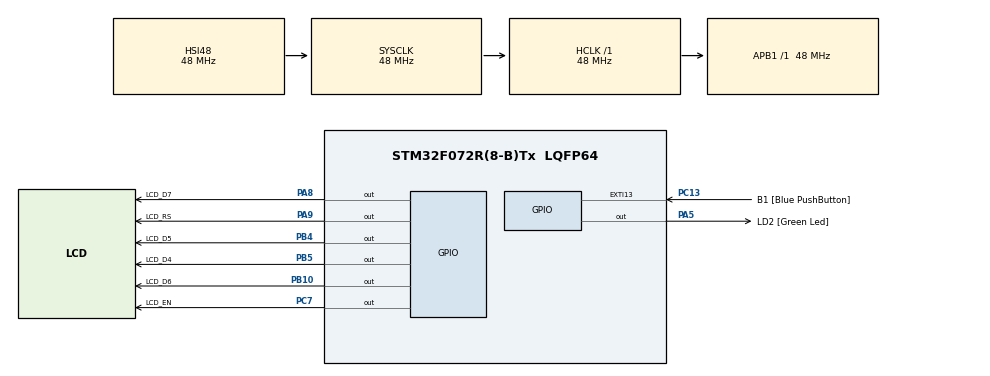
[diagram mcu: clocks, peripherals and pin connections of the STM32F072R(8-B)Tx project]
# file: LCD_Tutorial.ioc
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Mcu.Family=STM32F0
Mcu.Name=STM32F072R(8-B)Tx
Mcu.Package=LQFP64
PA13.GPIO_Label=TMS
PA13.Mode=Serial_Wire
PA13.Signal=SYS_SWDIO
PA14.GPIO_Label=TCK
PA14.Mode=Serial_Wire
PA14.Signal=SYS_SWCLK
PA2.GPIO_Label=USART_TX
PA2.GPIO_Mode=GPIO_MODE_AF_PP
PA2.GPIO_PuPd=GPIO_NOPULL
PA2.GPIO_Speed=GPIO_SPEED_FREQ_LOW
PA2.Signal=USART2_TX
PA3.GPIO_Label=USART_RX
PA3.GPIO_Mode=GPIO_MODE_AF_PP
PA3.GPIO_PuPd=GPIO_NOPULL
PA3.GPIO_Speed=GPIO_SPEED_FREQ_LOW
PA3.Signal=USART2_RX
PA5.GPIO_Label=LD2 [Green Led]
PA5.GPIO_Mode=GPIO_MODE_OUTPUT_PP
PA5.GPIO_PuPd=GPIO_NOPULL
PA5.GPIO_Speed=GPIO_SPEED_FREQ_LOW
PA5.Signal=GPIO_Output
PA8.GPIO_Label=LCD_D7
PA8.Signal=GPIO_Output
PA9.GPIO_Label=LCD_RS
PA9.Signal=GPIO_Output
PB10.GPIO_Label=LCD_D6
PB10.Signal=GPIO_Output
PB4.GPIO_Label=LCD_D5
PB4.Signal=GPIO_Output
PB5.GPIO_Label=LCD_D4
PB5.GPIO_Speed=GPIO_SPEED_FREQ_LOW
PB5.Signal=GPIO_Output
PC13.GPIO_Label=B1 [Blue PushButton]
PC13.GPIO_ModeDefaultEXTI=GPIO_MODE_IT_FALLING
PC13.Signal=GPXTI13
PC14-OSC32_IN.Signal=RCC_OSC32_IN
PC15-OSC32_OUT.Signal=RCC_OSC32_OUT
PC7.GPIO_Label=LCD_EN
PC7.Signal=GPIO_Output
PF0-OSC_IN.Signal=RCC_OSC_IN
PF1-OSC_OUT.Signal=RCC_OSC_OUT
ProjectManager.HeapSize=0x200
ProjectManager.StackSize=0x400
ProjectManager.TargetToolchain=MDK-ARM V5
RCC.AHBFreq_Value=48000000
RCC.APB1Freq_Value=48000000
RCC.APB1TimFreq_Value=48000000
RCC.FLatency-AdvancedSettings=FLASH_LATENCY_1
RCC.HCLKFreq_Value=48000000
RCC.PLLDivider=RCC_PREDIV_DIV2
RCC.PLLMUL=RCC_PLL_MUL12
RCC.PREFETCH_ENABLE-AdvancedSettings=1
RCC.SYSCLKFreq_VALUE=48000000
RCC.SYSCLKSource=RCC_SYSCLKSOURCE_HSI48
board=NUCLEO-F072RB

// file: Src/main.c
/* USER CODE BEGIN Header */
/**
  ******************************************************************************
  * @file           : main.c
  * @brief          : Main program body
  ******************************************************************************
  * @attention
  *
  * <h2><center>&copy; Copyright (c) 2020 STMicroelectronics.
  * All rights reserved.</center></h2>
  *
  * This software component is licensed by ST under BSD 3-Clause license,
  * the "License"; You may not use this file except in compliance with the
  * License. You may obtain a copy of the License at:
  *                        opensource.org/licenses/BSD-3-Clause
  *
  ******************************************************************************
  */
/* USER CODE END Header */

#include "main.h"

/* USER CODE BEGIN Includes */
#include "stdio.h"
#include "LCD.h"

/* USER CODE END Includes */

/* USER CODE BEGIN PM */

char line1[16];
int counter=0;

/* USER CODE END PM */

void SystemClock_Config(void);
static void MX_GPIO_Init(void);

int main(void)
{

  /* MCU Configuration--------------------------------------------------------*/

  /* Reset of all peripherals, Initializes the Flash interface and the Systick. */
  HAL_Init();

  /* Configure the system clock */
  SystemClock_Config();

  /* Initialize all configured peripherals */
  MX_GPIO_Init();
  /* USER CODE BEGIN 2 */
  lcd_init(_LCD_4BIT, _LCD_FONT_5x8, _LCD_2LINE);
	lcd_print(1,1,"Hello World");
  HAL_Delay(1000);
  lcd_clear();

  /* USER CODE END 2 */

  /* Infinite loop */
  while (1)
  {

    /* USER CODE BEGIN 3 */
	counter++;
	sprintf(line1,"Counter = %d ",counter);
	lcd_print(1,1,line1);
	HAL_Delay(1000);
  }
  /* USER CODE END 3 */
}

void SystemClock_Config(void)
{
  RCC_OscInitTypeDef RCC_OscInitStruct = {0};
  RCC_ClkInitTypeDef RCC_ClkInitStruct = {0};

  /** Initializes the CPU, AHB and APB busses clocks
  */
  RCC_OscInitStruct.OscillatorType = RCC_OSCILLATORTYPE_HSI48;
  RCC_OscInitStruct.HSI48State = RCC_HSI48_ON;
  RCC_OscInitStruct.PLL.PLLState = RCC_PLL_NONE;
  if (HAL_RCC_OscConfig(&RCC_OscInitStruct) != HAL_OK)
  {
    Error_Handler();
  }
  /** Initializes the CPU, AHB and APB busses clocks
  */
  RCC_ClkInitStruct.ClockType = RCC_CLOCKTYPE_HCLK|RCC_CLOCKTYPE_SYSCLK
                              |RCC_CLOCKTYPE_PCLK1;
  RCC_ClkInitStruct.SYSCLKSource = RCC_SYSCLKSOURCE_HSI48;
  RCC_ClkInitStruct.AHBCLKDivider = RCC_SYSCLK_DIV1;
  RCC_ClkInitStruct.APB1CLKDivider = RCC_HCLK_DIV1;

  if (HAL_RCC_ClockConfig(&RCC_ClkInitStruct, FLASH_LATENCY_1) != HAL_OK)
  {
    Error_Handler();
  }
}

static void MX_GPIO_Init(void)
{
  GPIO_InitTypeDef GPIO_InitStruct = {0};

  /* GPIO Ports Clock Enable */
  __HAL_RCC_GPIOC_CLK_ENABLE();
  __HAL_RCC_GPIOF_CLK_ENABLE();
  __HAL_RCC_GPIOA_CLK_ENABLE();
  __HAL_RCC_GPIOB_CLK_ENABLE();

  /*Configure GPIO pin Output Level */
  HAL_GPIO_WritePin(GPIOA, LD2_Pin|LCD_D7_Pin|LCD_RS_Pin, GPIO_PIN_RESET);

  /*Configure GPIO pin Output Level */
  HAL_GPIO_WritePin(GPIOB, LCD_D6_Pin|LCD_D5_Pin|LCD_D4_Pin, GPIO_PIN_RESET);

  /*Configure GPIO pin Output Level */
  HAL_GPIO_WritePin(LCD_EN_GPIO_Port, LCD_EN_Pin, GPIO_PIN_RESET);

  /*Configure GPIO pin : B1_Pin */
  GPIO_InitStruct.Pin = B1_Pin;
  GPIO_InitStruct.Mode = GPIO_MODE_IT_FALLING;
  GPIO_InitStruct.Pull = GPIO_NOPULL;
  HAL_GPIO_Init(B1_GPIO_Port, &GPIO_InitStruct);

  /*Configure GPIO pins : USART_TX_Pin USART_RX_Pin */
  GPIO_InitStruct.Pin = USART_TX_Pin|USART_RX_Pin;
  GPIO_InitStruct.Mode = GPIO_MODE_AF_PP;
  GPIO_InitStruct.Pull = GPIO_NOPULL;
  GPIO_InitStruct.Speed = GPIO_SPEED_FREQ_LOW;
  GPIO_InitStruct.Alternate = GPIO_AF1_USART2;
  HAL_GPIO_Init(GPIOA, &GPIO_InitStruct);

  /*Configure GPIO pins : LD2_Pin LCD_D7_Pin LCD_RS_Pin */
  GPIO_InitStruct.Pin = LD2_Pin|LCD_D7_Pin|LCD_RS_Pin;
  GPIO_InitStruct.Mode = GPIO_MODE_OUTPUT_PP;
  GPIO_InitStruct.Pull = GPIO_NOPULL;
  GPIO_InitStruct.Speed = GPIO_SPEED_FREQ_LOW;
  HAL_GPIO_Init(GPIOA, &GPIO_InitStruct);

  /*Configure GPIO pins : LCD_D6_Pin LCD_D5_Pin LCD_D4_Pin */
  GPIO_InitStruct.Pin = LCD_D6_Pin|LCD_D5_Pin|LCD_D4_Pin;
  GPIO_InitStruct.Mode = GPIO_MODE_OUTPUT_PP;
  GPIO_InitStruct.Pull = GPIO_NOPULL;
  GPIO_InitStruct.Speed = GPIO_SPEED_FREQ_LOW;
  HAL_GPIO_Init(GPIOB, &GPIO_InitStruct);

  /*Configure GPIO pin : LCD_EN_Pin */
  GPIO_InitStruct.Pin = LCD_EN_Pin;
  GPIO_InitStruct.Mode = GPIO_MODE_OUTPUT_PP;
  GPIO_InitStruct.Pull = GPIO_NOPULL;
  GPIO_InitStruct.Speed = GPIO_SPEED_FREQ_LOW;
  HAL_GPIO_Init(LCD_EN_GPIO_Port, &GPIO_InitStruct);

}

void Error_Handler(void)
{
}

/************************ (C) COPYRIGHT STMicroelectronics *****END OF FILE****/
